# GD32F30x_HD register map
File version: 1.0
CPU: CM4 r2p1, little endian, MPU, FPU, 4 interrupt priority bits
Registers are 32-bit, read-write, reset 0x0 unless marked. A register's access mark holds for its fields unless they carry their own. Offsets are from the block's base; [hi:lo] are bit positions; {n}, {i} and the like mark numbered series.

## AFIO — Alternate-function I/Os
Base 0x40010000
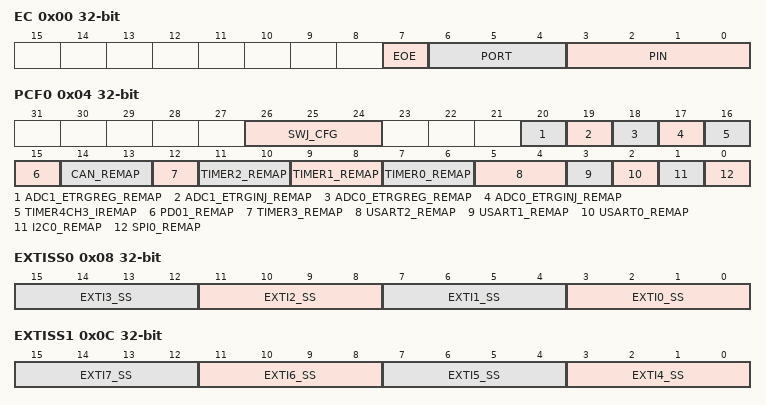
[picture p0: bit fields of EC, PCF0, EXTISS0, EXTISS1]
0x00 EC — Event control register
  [7] EOE — Event output enable
  [6:4] PORT — Event output port selection
  [3:0] PIN — Event output pin selection
0x04 PCF0 — AFIO port configuration register 0
  [26:24] SWJ_CFG — Serial wire JTAG configuration
  [20] ADC1_ETRGREG_REMAP — ADC 1 external trigger regular conversion remapping
  [19] ADC1_ETRGINJ_REMAP — ADC 1 external trigger injected conversion remapping
  [18] ADC0_ETRGREG_REMAP — ADC 0 external trigger regular conversion remapping
  [17] ADC0_ETRGINJ_REMAP — ADC 0 external trigger injected conversion remapping
  [16] TIMER4CH3_IREMAP — TIMER4 channel3 internal remapping
  [15] PD01_REMAP — Port D0/Port D1 mapping on OSC_IN/OSC_OUT
  [14:13] CAN_REMAP — CAN interface remapping
  [12] TIMER3_REMAP — TIMER3 remapping
  [11:10] TIMER2_REMAP — TIMER2 remapping
  [9:8] TIMER1_REMAP — TIMER1 remapping
  [7:6] TIMER0_REMAP — TIMER0 remapping
  [5:4] USART2_REMAP — USART2 remapping
  [3] USART1_REMAP — USART1 remapping
  [2] USART0_REMAP — USART0 remapping
  [1] I2C0_REMAP — I2C0 remapping
  [0] SPI0_REMAP — SPI0 remapping
0x08 EXTISS0 — EXTI sources selection register 0
  [4n+3:4n] EXTI{n}_SS (n=0..3) — EXTI {n} sources selection
0x0C EXTISS1 — EXTI sources selection register 1
  [4n-13:4n-16] EXTI{n}_SS (n=4..7) — EXTI {n} sources selection
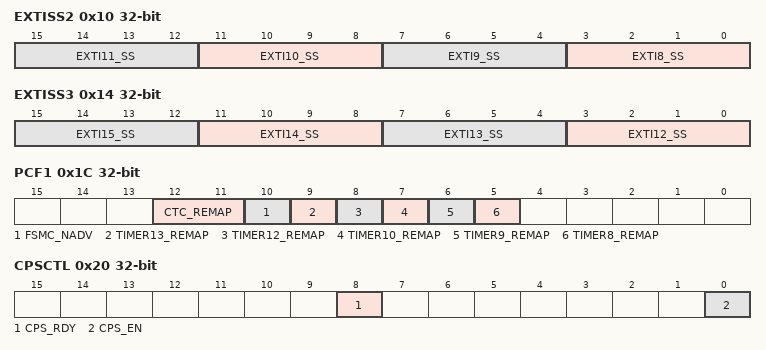
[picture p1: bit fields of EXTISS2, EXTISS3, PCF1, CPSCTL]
0x10 EXTISS2 — EXTI sources selection register 2
  [4n-29:4n-32] EXTI{n}_SS (n=8..11) — EXTI {n} sources selection
0x14 EXTISS3 — EXTI sources selection register 3
  [4n-45:4n-48] EXTI{n}_SS (n=12..15) — EXTI {n} sources selection
0x1C PCF1 — AFIO port configuration register 1
  [12:11] CTC_REMAP — CTC remapping
  [10] FSMC_NADV — FSMC_NADV connect/disconnect
  [9] TIMER13_REMAP — TIMER13 remapping
  [8] TIMER12_REMAP — TIMER12 remapping
  [7] TIMER10_REMAP — TIMER10 remapping
  [6] TIMER9_REMAP — TIMER9 remapping
  [5] TIMER8_REMAP — TIMER8 remapping
0x20 CPSCTL — IO compensation control register
  [8] CPS_RDY — I/O compensation cell is really or not
  [0] CPS_EN — I/O compensation cell enable

## BKP — Backup registers
Base 0x40006C00
{0x4+4i} DATA{i} (i=0..9) — Backup data register {i}
  [15:0] DATA — Backup data
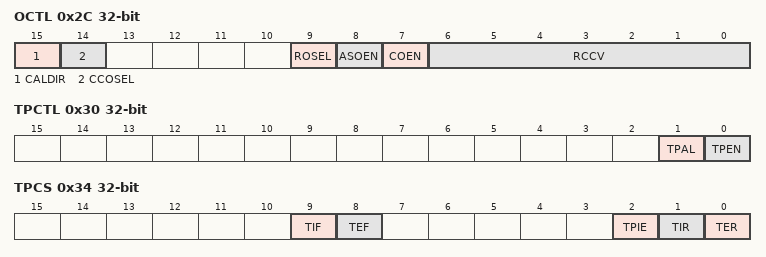
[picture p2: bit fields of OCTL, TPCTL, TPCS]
0x2C OCTL — RTC signal output control register
  [15] CALDIR — RTC clock calibration direction
  [14] CCOSEL — RTC clock output selection
  [9] ROSEL — RTC output selection
  [8] ASOEN — RTC alarm or second signal output enable
  [7] COEN — RTC clock calibration output enable
  [6:0] RCCV — RTC clock calibration value
0x30 TPCTL — Tamper pin control register
  [1] TPAL — TAMPER pin active level
  [0] TPEN — TAMPER detection enable
0x34 TPCS — Tamper control and status register
  [9] TIF — Tamper interrupt flag
  [8] TEF — Tamper event flag
  [2] TPIE — Tamper interrupt enable
  [1] TIR — Tamper interrupt reset
  [0] TER — Tamper event reset
{0x18+4i} DATA{i} (i=10..41) — Backup data register {i}
  [15:0] DATA — Backup data

## CRC — cyclic redundancy check calculation unit
Base 0x40023000
0x00 DATA reset 0xFFFFFFFF
  [31:0] DATA — CRC calculation result bits
0x04 FDATA — Free data register
  [7:0] FDATA — Free Data Register bits
0x08 CTL — Control register
  [0] RST — reset bit

## CTC — Clock trim controller
Base 0x4000C800
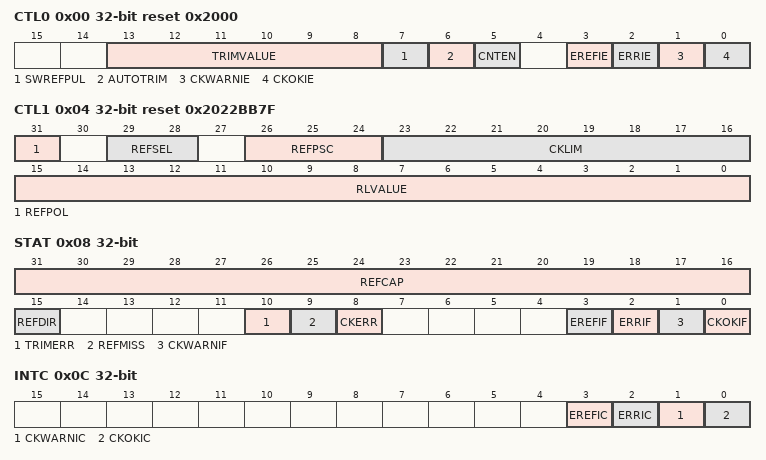
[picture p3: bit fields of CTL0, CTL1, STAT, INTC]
0x00 CTL0 reset 0x2000 — Control register 0
  [13:8] TRIMVALUE — IRC48M trim value
  [7] SWREFPUL — Software reference source sync pulse
  [6] AUTOTRIM — Hardware automatically trim mode
  [5] CNTEN — CTC counter enable
  [3] EREFIE — EREFIF interrupt enable
  [2] ERRIE — Error interrupt enable
  [1] CKWARNIE — Clock trim warning interrupt enable
  [0] CKOKIE — Clock trim ok interrupt enable
0x04 CTL1 reset 0x2022BB7F — Control register 1
  [31] REFPOL — Reference signal source polarity
  [29:28] REFSEL — Reference signal source selection
  [26:24] REFPSC — Reference signal source prescaler
  [23:16] CKLIM — Clock trim base limit value
  [15:0] RLVALUE — CTC counter reload value
0x08 STAT ro — Status register
  [31:16] REFCAP — CTC counter capture when reference sync pulse
  [15] REFDIR — CTC trim counter direction when reference sync pulse
  [10] TRIMERR — Trim value error bit
  [9] REFMISS — Reference sync pulse miss
  [8] CKERR — Clock trim error bit
  [3] EREFIF — Expect reference interrupt flag
  [2] ERRIF — Error interrupt flag
  [1] CKWARNIF — Clock trim warning interrupt flag
  [0] CKOKIF — Clock trim OK interrupt flag
0x0C INTC wo — Interrupt clear register
  [3] EREFIC — EREFIF interrupt clear bit
  [2] ERRIC — ERRIF interrupt clear bit
  [1] CKWARNIC — CKWARNIF interrupt clear bit
  [0] CKOKIC — CKOKIF interrupt clear bit
